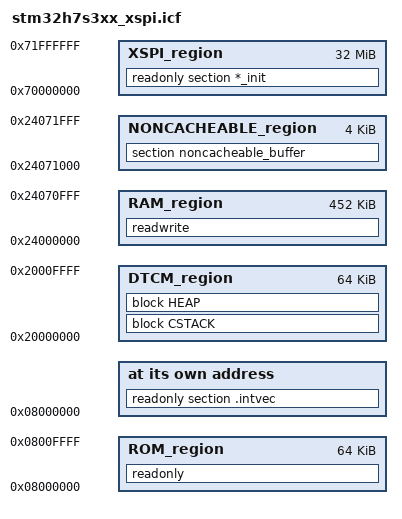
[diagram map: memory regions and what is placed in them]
/*
 * STM32H7S3xx: boot from internal flash, run from AXI SRAM, image stored on XSPI2 flash
 *
 * The vector table and the boot code (.boot_text, xspi_boot.c) stay in internal flash.
 * Reset_Handler maps the XSPI2 flash, then the IAR startup copies the image to RAM
 * ("initialize by copy" below): the initializers are placed in XSPI_region, the copies in
 * RAM_region.
 *
 * ILINK leaves out of the copy what it marks 'possibly needed for init': its startup
 * routines, and everything reachable from the vector table (the IRQ handlers and what they
 * call), as an interrupt could come before the copy. That code stays in internal flash
 * (ROM_region), which bounds it to 64 KB.
 *
 * AXI SRAM is 456 KB with the default option bytes (no ITCM/DTCM share, no ECC).
 */

define symbol __ICFEDIT_intvec_start__ = 0x08000000;

define symbol NONCACHEABLEBUFFER_size   = 0x1000; /* RTT control block and buffers (BUFFER_SIZE_UP) */

define symbol __ICFEDIT_region_ROM_start__ = 0x08000000;
define symbol __ICFEDIT_region_ROM_end__   = 0x0800FFFF;
define symbol __region_XSPI_start__        = 0x70000000;
define symbol __region_XSPI_end__          = 0x71FFFFFF;
define symbol __ICFEDIT_region_RAM_start__ = 0x24000000;
define symbol __ICFEDIT_region_RAM_end__   = 0x24071FFF - NONCACHEABLEBUFFER_size;
define symbol NONCACHEABLEBUFFER_start     = __ICFEDIT_region_RAM_end__ + 1;
define symbol NONCACHEABLEBUFFER_end       = __ICFEDIT_region_RAM_end__ + NONCACHEABLEBUFFER_size;

define symbol __ICFEDIT_size_cstack__ = 0x400;
define symbol __ICFEDIT_size_heap__   = 0x200;

define symbol __region_DTCM_start__ = 0x20000000;
define symbol __region_DTCM_end__   = 0x2000FFFF;

/* MPU_Config() makes the ROM region executable: keep it the internal flash */
export symbol NONCACHEABLEBUFFER_start;
export symbol NONCACHEABLEBUFFER_size;
export symbol __ICFEDIT_region_ROM_start__;
export symbol __ICFEDIT_region_ROM_end__;

define memory mem with size = 4G;
define region ROM_region          = mem:[from __ICFEDIT_region_ROM_start__ to __ICFEDIT_region_ROM_end__];
define region XSPI_region         = mem:[from __region_XSPI_start__ to __region_XSPI_end__];
define region RAM_region          = mem:[from __ICFEDIT_region_RAM_start__ to __ICFEDIT_region_RAM_end__];
define region NONCACHEABLE_region = mem:[from NONCACHEABLEBUFFER_start to NONCACHEABLEBUFFER_end];
define region DTCM_region         = mem:[from __region_DTCM_start__ to __region_DTCM_end__];

define block CSTACK    with alignment = 8, size = __ICFEDIT_size_cstack__   { };
define block HEAP      with alignment = 8, size = __ICFEDIT_size_heap__     { };

initialize by copy with packing = none { readonly, readwrite }
  except { readonly section .intvec, readonly section .boot_text };
do not initialize  { section .noinit };

/* nothing references the vector table (Reset_Handler sets VTOR to FLASH_BASE) */
keep { section .intvec };
place at address mem:__ICFEDIT_intvec_start__ { readonly section .intvec };

/* boot code, and what is 'needed for init' (see above) */
place in ROM_region   { readonly };
place in XSPI_region  { readonly section *_init };
place in RAM_region   { readwrite };
place in NONCACHEABLE_region { section noncacheable_buffer };
place in DTCM_region  { block CSTACK, block HEAP };
